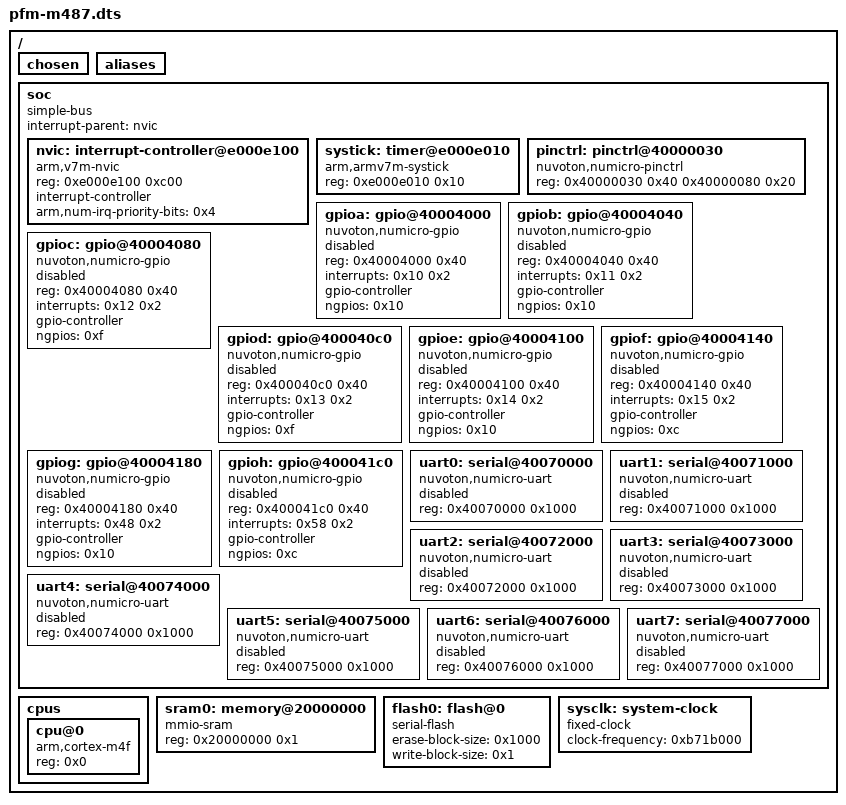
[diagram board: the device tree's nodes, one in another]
/dts-v1/;

/ {
	#address-cells = < 0x1 >;
	#size-cells = < 0x1 >;
	chosen {
	};
	aliases {
	};
	soc {
		#address-cells = < 0x1 >;
		#size-cells = < 0x1 >;
		compatible = "simple-bus";
		interrupt-parent = < &nvic >;
		ranges;
		nvic: interrupt-controller@e000e100 {
			#address-cells = < 0x1 >;
			compatible = "arm,v7m-nvic";
			reg = < 0xe000e100 0xc00 >;
			interrupt-controller;
			#interrupt-cells = < 0x2 >;
			arm,num-irq-priority-bits = < 0x4 >;
			phandle = < 0x1 >;
		};
		systick: timer@e000e010 {
			compatible = "arm,armv7m-systick";
			reg = < 0xe000e010 0x10 >;
		};
		pinctrl: pinctrl@40000030 {
			compatible = "nuvoton,numicro-pinctrl";
			reg = < 0x40000030 0x40 0x40000080 0x20 >;
			reg-names = "mfp", "mfos";
			status = "okay";
		};
		gpioa: gpio@40004000 {
			compatible = "nuvoton,numicro-gpio";
			reg = < 0x40004000 0x40 >;
			status = "disabled";
			interrupts = < 0x10 0x2 >;
			gpio-controller;
			#gpio-cells = < 0x2 >;
			ngpios = < 0x10 >;
		};
		gpiob: gpio@40004040 {
			compatible = "nuvoton,numicro-gpio";
			reg = < 0x40004040 0x40 >;
			status = "disabled";
			interrupts = < 0x11 0x2 >;
			gpio-controller;
			#gpio-cells = < 0x2 >;
			ngpios = < 0x10 >;
		};
		gpioc: gpio@40004080 {
			compatible = "nuvoton,numicro-gpio";
			reg = < 0x40004080 0x40 >;
			status = "disabled";
			interrupts = < 0x12 0x2 >;
			gpio-controller;
			#gpio-cells = < 0x2 >;
			ngpios = < 0xf >;
		};
		gpiod: gpio@400040c0 {
			compatible = "nuvoton,numicro-gpio";
			reg = < 0x400040c0 0x40 >;
			status = "disabled";
			interrupts = < 0x13 0x2 >;
			gpio-controller;
			#gpio-cells = < 0x2 >;
			ngpios = < 0xf >;
		};
		gpioe: gpio@40004100 {
			compatible = "nuvoton,numicro-gpio";
			reg = < 0x40004100 0x40 >;
			status = "disabled";
			interrupts = < 0x14 0x2 >;
			gpio-controller;
			#gpio-cells = < 0x2 >;
			ngpios = < 0x10 >;
		};
		gpiof: gpio@40004140 {
			compatible = "nuvoton,numicro-gpio";
			reg = < 0x40004140 0x40 >;
			status = "disabled";
			interrupts = < 0x15 0x2 >;
			gpio-controller;
			#gpio-cells = < 0x2 >;
			ngpios = < 0xc >;
		};
		gpiog: gpio@40004180 {
			compatible = "nuvoton,numicro-gpio";
			reg = < 0x40004180 0x40 >;
			status = "disabled";
			interrupts = < 0x48 0x2 >;
			gpio-controller;
			#gpio-cells = < 0x2 >;
			ngpios = < 0x10 >;
		};
		gpioh: gpio@400041c0 {
			compatible = "nuvoton,numicro-gpio";
			reg = < 0x400041c0 0x40 >;
			status = "disabled";
			interrupts = < 0x58 0x2 >;
			gpio-controller;
			#gpio-cells = < 0x2 >;
			ngpios = < 0xc >;
		};
		uart0: serial@40070000 {
			compatible = "nuvoton,numicro-uart";
			reg = < 0x40070000 0x1000 >;
			status = "disabled";
		};
		uart1: serial@40071000 {
			compatible = "nuvoton,numicro-uart";
			reg = < 0x40071000 0x1000 >;
			status = "disabled";
		};
		uart2: serial@40072000 {
			compatible = "nuvoton,numicro-uart";
			reg = < 0x40072000 0x1000 >;
			status = "disabled";
		};
		uart3: serial@40073000 {
			compatible = "nuvoton,numicro-uart";
			reg = < 0x40073000 0x1000 >;
			status = "disabled";
		};
		uart4: serial@40074000 {
			compatible = "nuvoton,numicro-uart";
			reg = < 0x40074000 0x1000 >;
			status = "disabled";
		};
		uart5: serial@40075000 {
			compatible = "nuvoton,numicro-uart";
			reg = < 0x40075000 0x1000 >;
			status = "disabled";
		};
		uart6: serial@40076000 {
			compatible = "nuvoton,numicro-uart";
			reg = < 0x40076000 0x1000 >;
			status = "disabled";
		};
		uart7: serial@40077000 {
			compatible = "nuvoton,numicro-uart";
			reg = < 0x40077000 0x1000 >;
			status = "disabled";
		};
	};
	cpus {
		#address-cells = < 0x1 >;
		#size-cells = < 0x0 >;
		cpu@0 {
			device_type = "cpu";
			compatible = "arm,cortex-m4f";
			reg = < 0x0 >;
		};
	};
	sram0: memory@20000000 {
		compatible = "mmio-sram";
		reg = < 0x20000000 0x1 >;
	};
	flash0: flash@0 {
		compatible = "serial-flash";
		erase-block-size = < 0x1000 >;
		write-block-size = < 0x1 >;
	};
	sysclk: system-clock {
		compatible = "fixed-clock";
		clock-frequency = < 0xb71b000 >;
		#clock-cells = < 0x0 >;
	};
};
